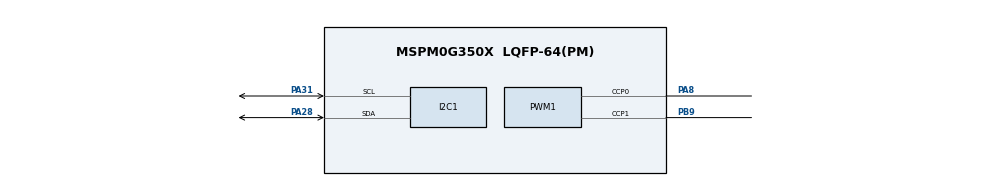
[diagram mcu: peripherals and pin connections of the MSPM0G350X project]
/**
 * @cliArgs --device "MSPM0G350X" --package "LQFP-64(PM)" --part "Default" --product "mspm0_sdk@2.01.00.03"
 * @versions {"tool":"1.20.0+3587"}
 */

/**
 * Import the modules used in this configuration.
 */
const ADC12  = scripting.addModule("/ti/driverlib/ADC12", {}, false);
const ADC121 = ADC12.addInstance();
const Board  = scripting.addModule("/ti/driverlib/Board");
const GPIO   = scripting.addModule("/ti/driverlib/GPIO", {}, false);
const GPIO1  = GPIO.addInstance();
const I2C    = scripting.addModule("/ti/driverlib/I2C", {}, false);
const I2C1   = I2C.addInstance();
const PWM    = scripting.addModule("/ti/driverlib/PWM", {}, false);
const PWM1   = PWM.addInstance();
const SYSCTL = scripting.addModule("/ti/driverlib/SYSCTL");
const TIMER  = scripting.addModule("/ti/driverlib/TIMER", {}, false);
const TIMER1 = TIMER.addInstance();
const TIMER2 = TIMER.addInstance();

/**
 * Write custom configuration values to the imported modules.
 */
ADC121.$name                             = "ADC12_0";
ADC121.repeatMode                        = true;
ADC121.powerDownMode                     = "DL_ADC12_POWER_DOWN_MODE_MANUAL";
ADC121.configureDMA                      = true;
ADC121.adcMem0chansel                    = "DL_ADC12_INPUT_CHAN_3";
ADC121.endAdd                            = 1;
ADC121.subChanID                         = 1;
ADC121.enabledDMATriggers                = ["DL_ADC12_DMA_MEM0_RESULT_LOADED"];
ADC121.sampCnt                           = 1;
ADC121.trigSrc                           = "DL_ADC12_TRIG_SRC_EVENT";
ADC121.adcMem0trig                       = "DL_ADC12_TRIGGER_MODE_TRIGGER_NEXT";
ADC121.sampleTime0                       = "10us";
ADC121.adcMem0wincomp                    = true;
ADC121.enabledInterrupts                 = ["DL_ADC12_INTERRUPT_DMA_DONE","DL_ADC12_INTERRUPT_MEM0_RESULT_LOADED","DL_ADC12_INTERRUPT_WINDOW_COMP_HIGH","DL_ADC12_INTERRUPT_WINDOW_COMP_LOW"];
ADC121.configWinCompLowThld              = 2047;
ADC121.configWinCompHighThld             = 2047;
ADC121.peripheral.$assign                = "ADC0";
ADC121.peripheral.adcPin3.$assign        = "PA24";
ADC121.DMA_CHANNEL.$name                 = "DMA_CH0";
ADC121.DMA_CHANNEL.addressMode           = "f2b";
ADC121.DMA_CHANNEL.transferMode          = "FULL_CH_REPEAT_SINGLE";
ADC121.DMA_CHANNEL.srcLength             = "HALF_WORD";
ADC121.DMA_CHANNEL.dstLength             = "HALF_WORD";
ADC121.DMA_CHANNEL.configureTransferSize = true;
ADC121.DMA_CHANNEL.transferSize          = 256;
ADC121.DMA_CHANNEL.peripheral.$assign    = "DMA_CH0";
ADC121.adcPin3Config.$name               = "ti_driverlib_gpio_GPIOPinGeneric0";


GPIO1.$name                              = "GPIO_SWITCHES";
GPIO1.associatedPins.create(8);
GPIO1.associatedPins[0].$name            = "SWITCH_1";
GPIO1.associatedPins[0].assignedPort     = "PORTB";
GPIO1.associatedPins[0].assignedPin      = "0";
GPIO1.associatedPins[1].$name            = "SWITCH_2";
GPIO1.associatedPins[1].assignedPort     = "PORTB";
GPIO1.associatedPins[1].assignedPin      = "16";
GPIO1.associatedPins[2].$name            = "SWITCH_3";
GPIO1.associatedPins[2].assignedPort     = "PORTA";
GPIO1.associatedPins[2].assignedPin      = "12";
GPIO1.associatedPins[3].$name            = "SWITCH_4";
GPIO1.associatedPins[3].assignedPort     = "PORTA";
GPIO1.associatedPins[3].assignedPin      = "13";
GPIO1.associatedPins[4].$name            = "SWITCH_5";
GPIO1.associatedPins[4].direction        = "INPUT";
GPIO1.associatedPins[4].internalResistor = "PULL_UP";
GPIO1.associatedPins[4].assignedPort     = "PORTB";
GPIO1.associatedPins[4].assignedPin      = "7";
GPIO1.associatedPins[5].$name            = "SWITCH_6";
GPIO1.associatedPins[5].internalResistor = "PULL_UP";
GPIO1.associatedPins[5].assignedPort     = "PORTB";
GPIO1.associatedPins[5].assignedPin      = "6";
GPIO1.associatedPins[5].direction        = "INPUT";
GPIO1.associatedPins[6].$name            = "SWITCH_7";
GPIO1.associatedPins[6].internalResistor = "PULL_UP";
GPIO1.associatedPins[6].assignedPort     = "PORTB";
GPIO1.associatedPins[6].assignedPin      = "13";
GPIO1.associatedPins[6].direction        = "INPUT";
GPIO1.associatedPins[7].$name            = "SWITCH_8";
GPIO1.associatedPins[7].assignedPort     = "PORTB";
GPIO1.associatedPins[7].assignedPin      = "20";
GPIO1.associatedPins[7].internalResistor = "PULL_UP";
GPIO1.associatedPins[7].direction        = "INPUT";

I2C1.$name                             = "I2C_OLED";
I2C1.basicEnableController             = true;
I2C1.intController                     = ["ARBITRATION_LOST","NACK","RXFIFO_TRIGGER","RX_DONE","TX_DONE"];
I2C1.basicControllerStandardBusSpeed   = "Fast";
I2C1.peripheral.sdaPin.$assign         = "PA28";
I2C1.peripheral.sclPin.$assign         = "PA31";
I2C1.sdaPinConfig.$name                = "ti_driverlib_gpio_GPIOPinGeneric1";
I2C1.sdaPinConfig.hideOutputInversion  = scripting.forceWrite(false);
I2C1.sdaPinConfig.onlyInternalResistor = scripting.forceWrite(false);
I2C1.sdaPinConfig.passedPeripheralType = scripting.forceWrite("Digital");
I2C1.sclPinConfig.$name                = "ti_driverlib_gpio_GPIOPinGeneric2";
I2C1.sclPinConfig.hideOutputInversion  = scripting.forceWrite(false);
I2C1.sclPinConfig.onlyInternalResistor = scripting.forceWrite(false);
I2C1.sclPinConfig.passedPeripheralType = scripting.forceWrite("Digital");

PWM1.$name                      = "PWM_0";
PWM1.clockDivider               = 8;
PWM1.clockPrescale              = 4;
PWM1.timerCount                 = 20000;
PWM1.pwmMode                    = "EDGE_ALIGN_UP";
PWM1.timerStartTimer            = true;
PWM1.peripheral.ccp0Pin.$assign = "PA8";
PWM1.peripheral.ccp1Pin.$assign = "PB9";
PWM1.PWM_CHANNEL_0.$name        = "ti_driverlib_pwm_PWMTimerCC0";
PWM1.PWM_CHANNEL_0.ccValue      = 1500;
PWM1.PWM_CHANNEL_1.$name        = "ti_driverlib_pwm_PWMTimerCC1";
PWM1.ccp0PinConfig.$name        = "ti_driverlib_gpio_GPIOPinGeneric3";
PWM1.ccp1PinConfig.$name        = "ti_driverlib_gpio_GPIOPinGeneric4";

SYSCTL.forceDefaultClkConfig = true;
SYSCTL.clockTreeEn           = true;

TIMER1.$name                       = "TIMER_0";
TIMER1.timerMode                   = "PERIODIC";
TIMER1.event1PublisherChannel      = 1;
TIMER1.event1ControllerInterruptEn = ["ZERO_EVENT"];
TIMER1.timerStartTimer             = true;
TIMER1.timerPeriod                 = "50us";

TIMER2.$name              = "TIMER_1";
TIMER2.timerMode          = "PERIODIC";
TIMER2.timerPeriod        = "50ms";
TIMER2.timerClkPrescale   = 4;
TIMER2.timerClkDiv        = 8;
TIMER2.interrupts         = ["ZERO"];
TIMER2.peripheral.$assign = "TIMG6";

/**
 * Pinmux solution for unlocked pins/peripherals. This ensures that minor changes to the automatic solver in a future
 * version of the tool will not impact the pinmux you originally saw.  These lines can be completely deleted in order to
 * re-solve from scratch.
 */
Board.peripheral.$suggestSolution            = "DEBUGSS";
Board.peripheral.swclkPin.$suggestSolution   = "PA20";
Board.peripheral.swdioPin.$suggestSolution   = "PA19";
GPIO1.associatedPins[0].pin.$suggestSolution = "PB0";
GPIO1.associatedPins[1].pin.$suggestSolution = "PB16";
GPIO1.associatedPins[2].pin.$suggestSolution = "PA12";
GPIO1.associatedPins[3].pin.$suggestSolution = "PA13";
GPIO1.associatedPins[4].pin.$suggestSolution = "PB7";
GPIO1.associatedPins[5].pin.$suggestSolution = "PB6";
GPIO1.associatedPins[6].pin.$suggestSolution = "PB13";
GPIO1.associatedPins[7].pin.$suggestSolution = "PB20";
I2C1.peripheral.$suggestSolution             = "I2C0";
PWM1.peripheral.$suggestSolution             = "TIMA0";
TIMER1.peripheral.$suggestSolution           = "TIMA1";
